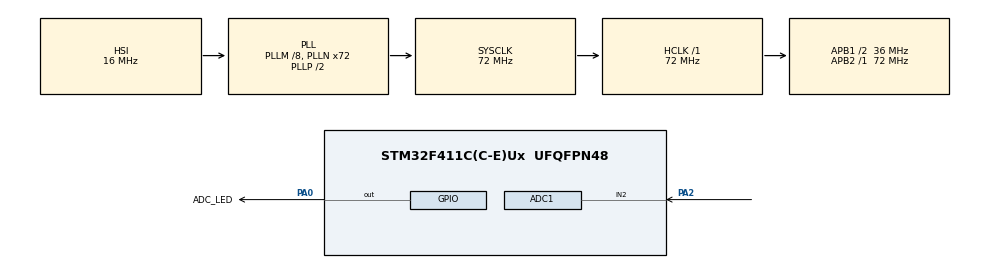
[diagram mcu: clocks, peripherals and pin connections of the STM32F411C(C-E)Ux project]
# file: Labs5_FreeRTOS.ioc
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ADC1.Channel-0\#ChannelRegularConversion=ADC_CHANNEL_2
ADC1.ContinuousConvMode=DISABLE
ADC1.NbrOfConversionFlag=1
ADC1.Rank-0\#ChannelRegularConversion=1
ADC1.SamplingTime-0\#ChannelRegularConversion=ADC_SAMPLETIME_3CYCLES
ADC1.master=1
Mcu.Family=STM32F4
Mcu.Name=STM32F411C(C-E)Ux
Mcu.Package=UFQFPN48
NVIC.ADC_IRQn=true\:0\:0\:false\:false\:true\:true\:true\:true
NVIC.PriorityGroup=NVIC_PRIORITYGROUP_4
PA0-WKUP.GPIO_Label=ADC_LED
PA0-WKUP.Signal=GPIO_Output
PA2.Signal=ADCx_IN2
ProjectManager.HeapSize=0x200
ProjectManager.StackSize=0x400
ProjectManager.TargetToolchain=STM32CubeIDE
RCC.48MHZClocksFreq_Value=36000000
RCC.AHBFreq_Value=72000000
RCC.APB1CLKDivider=RCC_HCLK_DIV2
RCC.APB1Freq_Value=36000000
RCC.APB1TimFreq_Value=72000000
RCC.APB2Freq_Value=72000000
RCC.APB2TimFreq_Value=72000000
RCC.CortexFreq_Value=72000000
RCC.HCLKFreq_Value=72000000
RCC.HSE_VALUE=25000000
RCC.HSI_VALUE=16000000
RCC.LSE_VALUE=32768
RCC.PLLM=8
RCC.PLLN=72
RCC.SYSCLKFreq_VALUE=72000000
RCC.SYSCLKSource=RCC_SYSCLKSOURCE_PLLCLK
RCC.VCOOutputFreq_Value=144000000
SH.ADCx_IN2.0=ADC1_IN2,IN2
board=custom

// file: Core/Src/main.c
/* USER CODE BEGIN Header */

/*Лабораторна робота 5 Програмування АЦП для реалізації функціонального вузла
радіотехнічної системи.

/* Підключення: 1 GND - [-ADC_LED+] - [резистор 325R] - PA0
 *              2 [Потенціометр]
 *                |      |     |
 *                Vcc   PA2   GND
 *               3.3 V
 * */

/* USER CODE END Header */
#include "main.h"

ADC_HandleTypeDef hadc1;

/* USER CODE BEGIN PV */

uint32_t adcValue = 0; // Змінна для зберігання значення з АЦП
float voltage = 0.0f;  // Значення вхідного сигналу з PA2 (у Вольтах)

/* USER CODE END PV */

void SystemClock_Config(void);
static void MX_GPIO_Init(void);
static void MX_ADC1_Init(void);

/* USER CODE BEGIN 0 */

// Обробник переривання (Callback)
void HAL_ADC_ConvCpltCallback(ADC_HandleTypeDef* hadc) {
    if (hadc->Instance == ADC1) { // Перевірка, який модуль виконав переривання

        adcValue = HAL_ADC_GetValue(hadc); // Зчитуємо значення (воно вже готове в регістрі)

        voltage = (adcValue * 3.3f) / 4096.0f; // Розрахунок напруги

        if (voltage > 0.5f) { // Керуємо світлодіодом на виході PA0
            HAL_GPIO_WritePin(ADC_LED_GPIO_Port, ADC_LED_Pin, GPIO_PIN_SET);
        } else {
            HAL_GPIO_WritePin(ADC_LED_GPIO_Port, ADC_LED_Pin, GPIO_PIN_RESET);
        }

        HAL_ADC_Start_IT(hadc); // Знову запускаємо АЦП для наступного вимірювання
        /*Для того, щоб програма автоматично запускала вимірювання АЦП після завершення попереднього.
         * В конфігурації проєкту можемо зробити наступне:
         * Continuous Conversion Mode: Enabled */
    }
}

/* USER CODE END 0 */

int main(void)
{

  /* MCU Configuration--------------------------------------------------------*/

  /* Reset of all peripherals, Initializes the Flash interface and the Systick. */
  HAL_Init();

  /* Configure the system clock */
  SystemClock_Config();

  /* Initialize all configured peripherals */
  MX_GPIO_Init();
  MX_ADC1_Init();
  /* USER CODE BEGIN 2 */

  HAL_ADC_Start_IT(&hadc1); // Запускаємо АЦП в режимі переривань

  /* USER CODE END 2 */

  /* Infinite loop */
  while (1)
  {

    /* USER CODE BEGIN 3 */

	  /*Тут можем виконувати будь-який інший код*/

	  HAL_Delay(1000); // Наприклад затримка, для наочності, що вона не буде зупиняти код обробника переривань
  }
  /* USER CODE END 3 */
}

void SystemClock_Config(void)
{
  RCC_OscInitTypeDef RCC_OscInitStruct = {0};
  RCC_ClkInitTypeDef RCC_ClkInitStruct = {0};

  /** Configure the main internal regulator output voltage
  */
  __HAL_RCC_PWR_CLK_ENABLE();
  __HAL_PWR_VOLTAGESCALING_CONFIG(PWR_REGULATOR_VOLTAGE_SCALE1);

  /** Initializes the RCC Oscillators according to the specified parameters
  * in the RCC_OscInitTypeDef structure.
  */
  RCC_OscInitStruct.OscillatorType = RCC_OSCILLATORTYPE_HSI;
  RCC_OscInitStruct.HSIState = RCC_HSI_ON;
  RCC_OscInitStruct.HSICalibrationValue = RCC_HSICALIBRATION_DEFAULT;
  RCC_OscInitStruct.PLL.PLLState = RCC_PLL_ON;
  RCC_OscInitStruct.PLL.PLLSource = RCC_PLLSOURCE_HSI;
  RCC_OscInitStruct.PLL.PLLM = 8;
  RCC_OscInitStruct.PLL.PLLN = 72;
  RCC_OscInitStruct.PLL.PLLP = RCC_PLLP_DIV2;
  RCC_OscInitStruct.PLL.PLLQ = 4;
  if (HAL_RCC_OscConfig(&RCC_OscInitStruct) != HAL_OK)
  {
    Error_Handler();
  }

  /** Initializes the CPU, AHB and APB buses clocks
  */
  RCC_ClkInitStruct.ClockType = RCC_CLOCKTYPE_HCLK|RCC_CLOCKTYPE_SYSCLK
                              |RCC_CLOCKTYPE_PCLK1|RCC_CLOCKTYPE_PCLK2;
  RCC_ClkInitStruct.SYSCLKSource = RCC_SYSCLKSOURCE_PLLCLK;
  RCC_ClkInitStruct.AHBCLKDivider = RCC_SYSCLK_DIV1;
  RCC_ClkInitStruct.APB1CLKDivider = RCC_HCLK_DIV2;
  RCC_ClkInitStruct.APB2CLKDivider = RCC_HCLK_DIV1;

  if (HAL_RCC_ClockConfig(&RCC_ClkInitStruct, FLASH_LATENCY_2) != HAL_OK)
  {
    Error_Handler();
  }
}

static void MX_ADC1_Init(void)
{

  ADC_ChannelConfTypeDef sConfig = {0};

  /** Configure the global features of the ADC (Clock, Resolution, Data Alignment and number of conversion)
  */
  hadc1.Instance = ADC1;
  hadc1.Init.ClockPrescaler = ADC_CLOCK_SYNC_PCLK_DIV2;
  hadc1.Init.Resolution = ADC_RESOLUTION_12B;
  hadc1.Init.ScanConvMode = DISABLE;
  hadc1.Init.ContinuousConvMode = DISABLE;
  hadc1.Init.DiscontinuousConvMode = DISABLE;
  hadc1.Init.ExternalTrigConvEdge = ADC_EXTERNALTRIGCONVEDGE_NONE;
  hadc1.Init.ExternalTrigConv = ADC_SOFTWARE_START;
  hadc1.Init.DataAlign = ADC_DATAALIGN_RIGHT;
  hadc1.Init.NbrOfConversion = 1;
  hadc1.Init.DMAContinuousRequests = DISABLE;
  hadc1.Init.EOCSelection = ADC_EOC_SINGLE_CONV;
  if (HAL_ADC_Init(&hadc1) != HAL_OK)
  {
    Error_Handler();
  }

  /** Configure for the selected ADC regular channel its corresponding rank in the sequencer and its sample time.
  */
  sConfig.Channel = ADC_CHANNEL_2;
  sConfig.Rank = 1;
  sConfig.SamplingTime = ADC_SAMPLETIME_3CYCLES;
  if (HAL_ADC_ConfigChannel(&hadc1, &sConfig) != HAL_OK)
  {
    Error_Handler();
  }

}

static void MX_GPIO_Init(void)
{
  GPIO_InitTypeDef GPIO_InitStruct = {0};

  /* GPIO Ports Clock Enable */
  __HAL_RCC_GPIOA_CLK_ENABLE();

  /*Configure GPIO pin Output Level */
  HAL_GPIO_WritePin(ADC_LED_GPIO_Port, ADC_LED_Pin, GPIO_PIN_RESET);

  /*Configure GPIO pin : ADC_LED_Pin */
  GPIO_InitStruct.Pin = ADC_LED_Pin;
  GPIO_InitStruct.Mode = GPIO_MODE_OUTPUT_PP;
  GPIO_InitStruct.Pull = GPIO_NOPULL;
  GPIO_InitStruct.Speed = GPIO_SPEED_FREQ_LOW;
  HAL_GPIO_Init(ADC_LED_GPIO_Port, &GPIO_InitStruct);

}

void Error_Handler(void)
{
  __disable_irq();
  while (1)
  {
  }
}
